AUTOSAR XML (schema 4-0-3)
package /add_pkg/add_swc
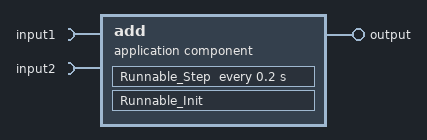
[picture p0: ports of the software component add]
  application sw component type add
    require port input1: nonqueued-receiver-com-spec{data-element=input1, init-value=0}, required-interface=input1
    require port input2: nonqueued-receiver-com-spec{data-element=input2, init-value=0}, required-interface=input2
    provide port output: nonqueued-sender-com-spec{data-element=output, init-value=0}, provided-interface=output
    behavior add: handle-termination-and-restart=NO-SUPPORT
      timing event Event_Runnable_Step: start-on-event=Runnable_Step, period=0.2
      runnable Runnable_Init
      runnable Runnable_Step
        data-read-access:
          access IN_input1_input1: accessed-variable=input1.input1
          access IN_input2_input2: accessed-variable=input2.input2
        data-write-access:
          access OUT_output_output: accessed-variable=output.output
